# MCU_CTRL_MMR0_CFG0 register map
Vendor: Texas Instruments
Peripheral module from a debugger description file (folder am243x).
Registers are 32-bit, read-write, reset 0x0 unless marked. A register's access mark holds for its fields unless they carry their own. Offsets are as the file gives them; lines under a group give offsets from that group; [hi:lo] are bit positions; {n}, {i} and the like mark numbered series; 'fields as' and 'values as' point back to an identical list; <NAME> marks a mode.

## MCU_CTRL_MMR0_CFG0 (part 1 of 2)
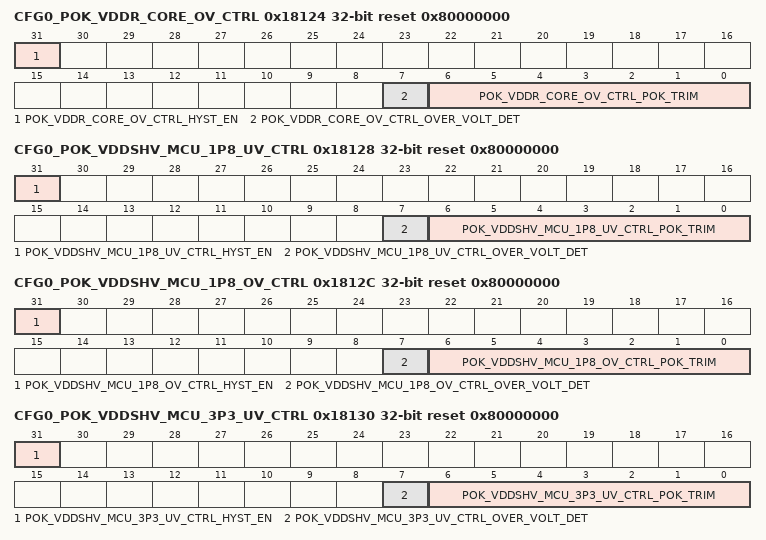
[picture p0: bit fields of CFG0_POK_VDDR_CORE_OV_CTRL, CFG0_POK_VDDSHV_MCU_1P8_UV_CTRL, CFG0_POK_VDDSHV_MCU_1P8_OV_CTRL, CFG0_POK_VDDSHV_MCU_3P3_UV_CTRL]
0x18124 CFG0_POK_VDDR_CORE_OV_CTRL reset 0x80000000
  [31] POK_VDDR_CORE_OV_CTRL_HYST_EN — Active POK hysteresis
  [7] POK_VDDR_CORE_OV_CTRL_OVER_VOLT_DET — Over / under voltage detection mode
  [6:0] POK_VDDR_CORE_OV_CTRL_POK_TRIM — POK Trim Bits
0x18128 CFG0_POK_VDDSHV_MCU_1P8_UV_CTRL reset 0x80000000
  [31] POK_VDDSHV_MCU_1P8_UV_CTRL_HYST_EN — Active POK hysteresis
  [7] POK_VDDSHV_MCU_1P8_UV_CTRL_OVER_VOLT_DET — Over / under voltage detection mode
  [6:0] POK_VDDSHV_MCU_1P8_UV_CTRL_POK_TRIM — POK Trim Bits
0x1812C CFG0_POK_VDDSHV_MCU_1P8_OV_CTRL reset 0x80000000
  [31] POK_VDDSHV_MCU_1P8_OV_CTRL_HYST_EN — Active POK hysteresis
  [7] POK_VDDSHV_MCU_1P8_OV_CTRL_OVER_VOLT_DET — Over / under voltage detection mode
  [6:0] POK_VDDSHV_MCU_1P8_OV_CTRL_POK_TRIM — POK Trim Bits
0x18130 CFG0_POK_VDDSHV_MCU_3P3_UV_CTRL reset 0x80000000
  [31] POK_VDDSHV_MCU_3P3_UV_CTRL_HYST_EN — Active POK hysteresis
  [7] POK_VDDSHV_MCU_3P3_UV_CTRL_OVER_VOLT_DET — Over / under voltage detection mode
  [6:0] POK_VDDSHV_MCU_3P3_UV_CTRL_POK_TRIM — POK Trim Bits
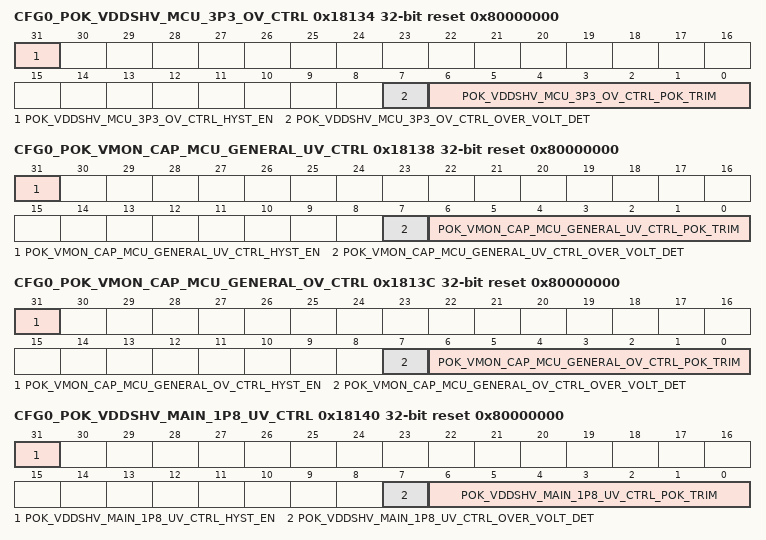
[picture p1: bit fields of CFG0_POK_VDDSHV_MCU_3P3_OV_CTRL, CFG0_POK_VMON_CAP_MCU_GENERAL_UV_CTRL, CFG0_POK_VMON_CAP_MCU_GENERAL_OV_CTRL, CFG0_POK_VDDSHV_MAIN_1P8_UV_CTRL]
0x18134 CFG0_POK_VDDSHV_MCU_3P3_OV_CTRL reset 0x80000000
  [31] POK_VDDSHV_MCU_3P3_OV_CTRL_HYST_EN — Active POK hysteresis
  [7] POK_VDDSHV_MCU_3P3_OV_CTRL_OVER_VOLT_DET — Over / under voltage detection mode
  [6:0] POK_VDDSHV_MCU_3P3_OV_CTRL_POK_TRIM — POK Trim Bits
0x18138 CFG0_POK_VMON_CAP_MCU_GENERAL_UV_CTRL reset 0x80000000
  [31] POK_VMON_CAP_MCU_GENERAL_UV_CTRL_HYST_EN — Active POK hysteresis
  [7] POK_VMON_CAP_MCU_GENERAL_UV_CTRL_OVER_VOLT_DET — Over / under voltage detection mode
  [6:0] POK_VMON_CAP_MCU_GENERAL_UV_CTRL_POK_TRIM — POK Trim Bits
0x1813C CFG0_POK_VMON_CAP_MCU_GENERAL_OV_CTRL reset 0x80000000
  [31] POK_VMON_CAP_MCU_GENERAL_OV_CTRL_HYST_EN — Active POK hysteresis
  [7] POK_VMON_CAP_MCU_GENERAL_OV_CTRL_OVER_VOLT_DET — Over / under voltage detection mode
  [6:0] POK_VMON_CAP_MCU_GENERAL_OV_CTRL_POK_TRIM — POK Trim Bits
0x18140 CFG0_POK_VDDSHV_MAIN_1P8_UV_CTRL reset 0x80000000
  [31] POK_VDDSHV_MAIN_1P8_UV_CTRL_HYST_EN — Active POK hysteresis
  [7] POK_VDDSHV_MAIN_1P8_UV_CTRL_OVER_VOLT_DET — Over / under voltage detection mode
  [6:0] POK_VDDSHV_MAIN_1P8_UV_CTRL_POK_TRIM — POK Trim Bits
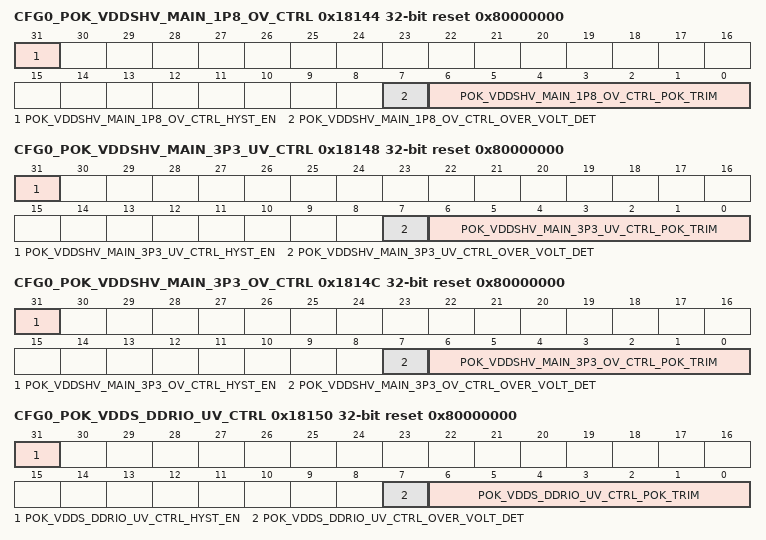
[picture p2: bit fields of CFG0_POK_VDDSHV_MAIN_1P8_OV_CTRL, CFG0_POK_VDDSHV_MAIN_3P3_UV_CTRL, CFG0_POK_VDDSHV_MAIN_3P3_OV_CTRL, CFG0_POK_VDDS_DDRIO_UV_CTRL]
0x18144 CFG0_POK_VDDSHV_MAIN_1P8_OV_CTRL reset 0x80000000
  [31] POK_VDDSHV_MAIN_1P8_OV_CTRL_HYST_EN — Active POK hysteresis
  [7] POK_VDDSHV_MAIN_1P8_OV_CTRL_OVER_VOLT_DET — Over / under voltage detection mode
  [6:0] POK_VDDSHV_MAIN_1P8_OV_CTRL_POK_TRIM — POK Trim Bits
0x18148 CFG0_POK_VDDSHV_MAIN_3P3_UV_CTRL reset 0x80000000
  [31] POK_VDDSHV_MAIN_3P3_UV_CTRL_HYST_EN — Active POK hysteresis
  [7] POK_VDDSHV_MAIN_3P3_UV_CTRL_OVER_VOLT_DET — Over / under voltage detection mode
  [6:0] POK_VDDSHV_MAIN_3P3_UV_CTRL_POK_TRIM — POK Trim Bits
0x1814C CFG0_POK_VDDSHV_MAIN_3P3_OV_CTRL reset 0x80000000
  [31] POK_VDDSHV_MAIN_3P3_OV_CTRL_HYST_EN — Active POK hysteresis
  [7] POK_VDDSHV_MAIN_3P3_OV_CTRL_OVER_VOLT_DET — Over / under voltage detection mode
  [6:0] POK_VDDSHV_MAIN_3P3_OV_CTRL_POK_TRIM — POK Trim Bits
0x18150 CFG0_POK_VDDS_DDRIO_UV_CTRL reset 0x80000000
  [31] POK_VDDS_DDRIO_UV_CTRL_HYST_EN — Active POK hysteresis
  [7] POK_VDDS_DDRIO_UV_CTRL_OVER_VOLT_DET — Over / under voltage detection mode
  [6:0] POK_VDDS_DDRIO_UV_CTRL_POK_TRIM — POK Trim Bits
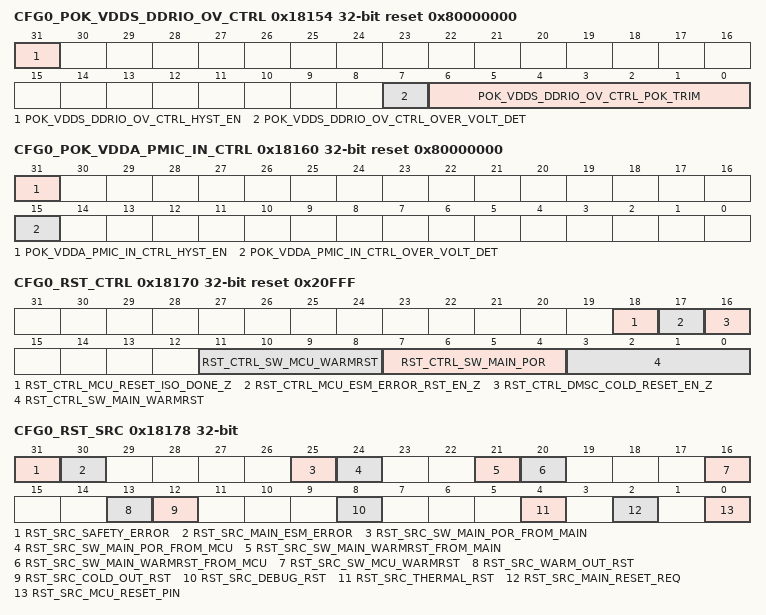
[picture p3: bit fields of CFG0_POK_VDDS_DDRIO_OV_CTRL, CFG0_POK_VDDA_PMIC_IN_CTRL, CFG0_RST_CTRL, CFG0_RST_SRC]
0x18154 CFG0_POK_VDDS_DDRIO_OV_CTRL reset 0x80000000
  [31] POK_VDDS_DDRIO_OV_CTRL_HYST_EN — Active POK hysteresis
  [7] POK_VDDS_DDRIO_OV_CTRL_OVER_VOLT_DET — Over / under voltage detection mode
  [6:0] POK_VDDS_DDRIO_OV_CTRL_POK_TRIM — POK Trim Bits
0x18160 CFG0_POK_VDDA_PMIC_IN_CTRL reset 0x80000000
  [31] POK_VDDA_PMIC_IN_CTRL_HYST_EN — Active POK hysteresis
  [15] POK_VDDA_PMIC_IN_CTRL_OVER_VOLT_DET — Over / under voltage detection mode
0x18170 CFG0_RST_CTRL reset 0x20FFF
  [18] RST_CTRL_MCU_RESET_ISO_DONE_Z — MCU can set this bit to block warm reset in the main domain which is useful when the MCU may be accessing
  [17] RST_CTRL_MCU_ESM_ERROR_RST_EN_Z — Deactivate Reset of MCU by ESM
  [16] RST_CTRL_DMSC_COLD_RESET_EN_Z — Deactivate Reset of MCU by DMSC
  [11:8] RST_CTRL_SW_MCU_WARMRST — This is a fault tolerant bitfield.
  [7:4] RST_CTRL_SW_MAIN_POR — This is a fault tolerant bitfield.
  [3:0] RST_CTRL_SW_MAIN_WARMRST — This is a fault tolerant bitfield.
0x18174 CFG0_RST_STAT ro
  [0] RST_STAT_MAIN_RESETSTATZ — Status of Main Domain Reset:
0x18178 CFG0_RST_SRC
  [31] RST_SRC_SAFETY_ERROR — Reset Caused by MCU ESM Error
  [30] RST_SRC_MAIN_ESM_ERROR — Reset Caused by Main ESM Error
  [25] RST_SRC_SW_MAIN_POR_FROM_MAIN — Software Main Power On Reset From MAIN CTRL MMR
  [24] RST_SRC_SW_MAIN_POR_FROM_MCU — Software Main Power On Reset From MCU CTRL MMR
  [21] RST_SRC_SW_MAIN_WARMRST_FROM_MAIN — Software Main Warm Reset from MAIN CTRL MMR
  [20] RST_SRC_SW_MAIN_WARMRST_FROM_MCU — Software Main Warm Reset From MCU CTRL MMR
  [16] RST_SRC_SW_MCU_WARMRST — Software Warm Reset
  [13] RST_SRC_WARM_OUT_RST — DMSC Warm Reset
  [12] RST_SRC_COLD_OUT_RST — DMSC Cold Reset
  [8] RST_SRC_DEBUG_RST — Debug Subsystem Initiated Reset
  [4] RST_SRC_THERMAL_RST — Thermal Reset
  [2] RST_SRC_MAIN_RESET_REQ — Main Reset Pin
  [0] RST_SRC_MCU_RESET_PIN — Rest Caused by MCU Reset Pin
0x1817C CFG0_RST_MAGIC_WORD
  [31:0] RST_MAGIC_WORD_MCU_MAGIC_WORD — After a MCU_PORz reset this bit field resets to 0x00000000.
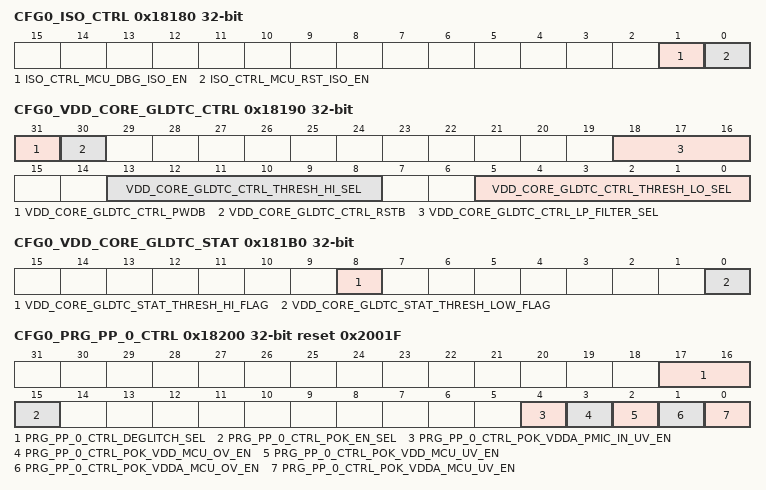
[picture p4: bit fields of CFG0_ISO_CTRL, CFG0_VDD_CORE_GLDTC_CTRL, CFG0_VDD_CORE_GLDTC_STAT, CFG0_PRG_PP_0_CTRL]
0x18180 CFG0_ISO_CTRL
  [1] ISO_CTRL_MCU_DBG_ISO_EN — Isolates the MCU domain from Debug
  [0] ISO_CTRL_MCU_RST_ISO_EN — Isolates the MCU domain from Warm Reset initiated by Main
0x18190 CFG0_VDD_CORE_GLDTC_CTRL
  [31] VDD_CORE_GLDTC_CTRL_PWDB — Power down - active low.
  [30] VDD_CORE_GLDTC_CTRL_RSTB — Reset - active low. To ensure proper operation, rstb must be not be de-asserted for at least 100 ns after power-up (pwdb de-asserted). Additionally, rstb must be toggled low at least 200 ns after any change in threshold or low-pass filter settings to prevent abnormal trigger events.
  [18:16] VDD_CORE_GLDTC_CTRL_LP_FILTER_SEL — Selects the glitch detect low-pass filter bandwidth
  [13:8] VDD_CORE_GLDTC_CTRL_THRESH_HI_SEL — Selects the high voltage glitch threshold as a percentage of the monitored voltage
  [5:0] VDD_CORE_GLDTC_CTRL_THRESH_LO_SEL — Selects the low voltage glitch threshold as a percentage of the monitored voltage
0x181B0 CFG0_VDD_CORE_GLDTC_STAT ro
  [8] VDD_CORE_GLDTC_STAT_THRESH_HI_FLAG — High voltage flag. This flag is cleared by clearing the VDD_CORE_GLDTC_CTRL_rstb bit.
  [0] VDD_CORE_GLDTC_STAT_THRESH_LOW_FLAG — Low voltage flag. This flag is cleared by clearing the VDD_CORE_GLDTC_CTRL_rstb bit.
0x18200 CFG0_PRG_PP_0_CTRL reset 0x2001F
  [17:16] PRG_PP_0_CTRL_DEGLITCH_SEL — Deglitch period for PRG_PP0 POKs:
  [15] PRG_PP_0_CTRL_POK_EN_SEL — Select POK active source
  [4] PRG_PP_0_CTRL_POK_VDDA_PMIC_IN_UV_EN — Active VDDA_PMIC_IN undervoltage POK detection
  [3] PRG_PP_0_CTRL_POK_VDD_MCU_OV_EN — Active VDD_MCU overvoltage POK detection
  [2] PRG_PP_0_CTRL_POK_VDD_MCU_UV_EN — Active VDD_MCU undervoltage POK detection
  [1] PRG_PP_0_CTRL_POK_VDDA_MCU_OV_EN — Active 1.8V VDDA_MCU overvoltage POK detection
  [0] PRG_PP_0_CTRL_POK_VDDA_MCU_UV_EN — Active 1.8V VDDA_MCU undervoltage POK detection
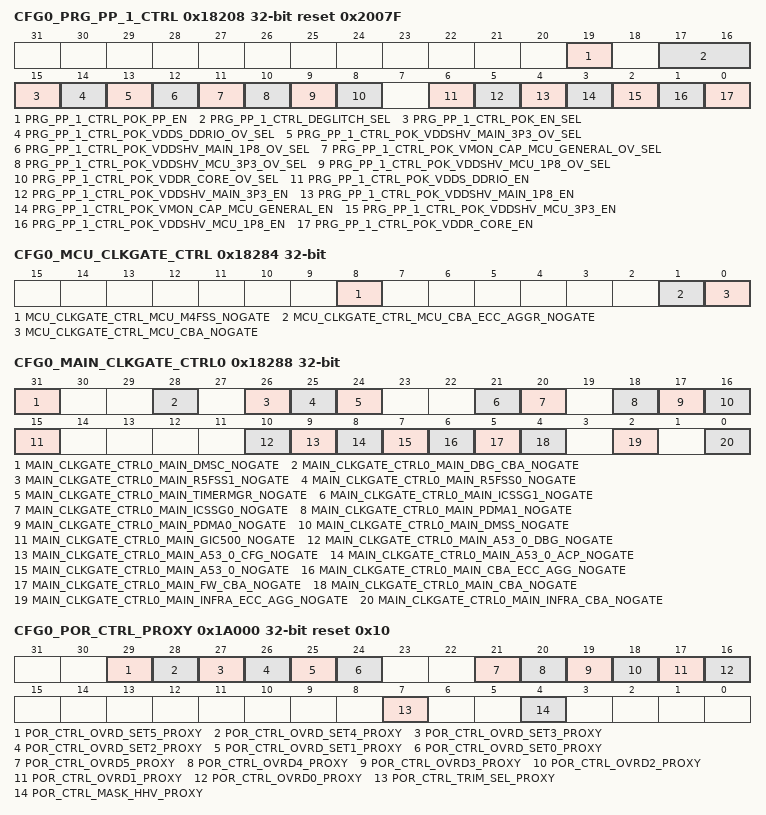
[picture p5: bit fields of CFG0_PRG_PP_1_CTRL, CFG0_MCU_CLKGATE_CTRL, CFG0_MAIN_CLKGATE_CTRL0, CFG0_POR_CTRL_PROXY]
0x18208 CFG0_PRG_PP_1_CTRL reset 0x2007F
  [19] PRG_PP_1_CTRL_POK_PP_EN — POK ping-pong active. When set, activesautomatic switching between undervoltage andovervoltage detection on PRG_PP1 (POK_VDDR_CORE, POK_VDDSHV_MCU_1P8, POK_VDDSHV_MCU_3P3, POK_VMON_CAP_MCU_GENERAL, POK_VDDSHV_MAIN_1P8, POK_VDDSHV_MAIN_3P3, and POK_VDDS_DDRIO) POKs. This bit has no effect if the POK's ov_sel bit = 1.
  [17:16] PRG_PP_1_CTRL_DEGLITCH_SEL — Deglitch period for PRG_PP1 POKs:
  [15] PRG_PP_1_CTRL_POK_EN_SEL — Select POK active source
  [14] PRG_PP_1_CTRL_POK_VDDS_DDRIO_OV_SEL — POK_VDDS_DDRIO mode:
  [13] PRG_PP_1_CTRL_POK_VDDSHV_MAIN_3P3_OV_SEL — POK_VDDSHV_MAIN_3P3 mode:
  [12] PRG_PP_1_CTRL_POK_VDDSHV_MAIN_1P8_OV_SEL — POK_VDDSHV_MAIN_1P8 mode:
  [11] PRG_PP_1_CTRL_POK_VMON_CAP_MCU_GENERAL_OV_SEL — POK_VMON_CAP_MCU_GENERAL mode:
  [10] PRG_PP_1_CTRL_POK_VDDSHV_MCU_3P3_OV_SEL — POK_VDDSHV_MCU_3P3 mode:
  [9] PRG_PP_1_CTRL_POK_VDDSHV_MCU_1P8_OV_SEL — POK_VDDSHV_MCU_1P8 mode:
  [8] PRG_PP_1_CTRL_POK_VDDR_CORE_OV_SEL — POK_VDDR_CORE Mode:
  [6] PRG_PP_1_CTRL_POK_VDDS_DDRIO_EN — Active POK_VDDS_DDRIO (if pok_en_sel = 1):
  [5] PRG_PP_1_CTRL_POK_VDDSHV_MAIN_3P3_EN — Active POK_VDDSHV_MAIN_3P3 (if pok_en_sel = 1):
  [4] PRG_PP_1_CTRL_POK_VDDSHV_MAIN_1P8_EN — Active POK_VDDSHV_MAIN_1P8 (if pok_en_sel = 1):
  [3] PRG_PP_1_CTRL_POK_VMON_CAP_MCU_GENERAL_EN — Active POK_VMON_CAP_MCU_GENERAL (if pok_en_sel = 1):
  [2] PRG_PP_1_CTRL_POK_VDDSHV_MCU_3P3_EN — Active POK_VDDSHV_MCU_3P3 (if pok_en_sel = 1):
  [1] PRG_PP_1_CTRL_POK_VDDSHV_MCU_1P8_EN — Active POK_VDDSHV_MCU_1P8 (if pok_en_sel = 1):
  [0] PRG_PP_1_CTRL_POK_VDDR_CORE_EN — Active POK_VDDR_CORE (if pok_en_sel = 1):
0x18284 CFG0_MCU_CLKGATE_CTRL
  [8] MCU_CLKGATE_CTRL_MCU_M4FSS_NOGATE — MCU domain M4FSS0 clock gate deactivate.
  [1] MCU_CLKGATE_CTRL_MCU_CBA_ECC_AGGR_NOGATE — MCU domain Pulsar clock gate deactivate.
  [0] MCU_CLKGATE_CTRL_MCU_CBA_NOGATE — MCU domain Data bus (mcu_cbass) clock gate deactivate.
0x18288 CFG0_MAIN_CLKGATE_CTRL0
  [31] MAIN_CLKGATE_CTRL0_MAIN_DMSC_NOGATE — MAIN domain DMSC (pwr_dis_nogate) clock gate deactivate.
  [28] MAIN_CLKGATE_CTRL0_MAIN_DBG_CBA_NOGATE — MAIN domain Debug bus clock gate deactivate.
  [26] MAIN_CLKGATE_CTRL0_MAIN_R5FSS1_NOGATE — MAIN domain R5FSS1 clock gate deactivate.
  [25] MAIN_CLKGATE_CTRL0_MAIN_R5FSS0_NOGATE — MAIN domain R5FSS0 clock gate deactivate.
  [24] MAIN_CLKGATE_CTRL0_MAIN_TIMERMGR_NOGATE — MAIN domain TIMERMGR (pwr_dis_nogate) clock gate deactivate.
  [21] MAIN_CLKGATE_CTRL0_MAIN_ICSSG1_NOGATE — MAIN domain ICSSG1 clock gate deactivate.
  [20] MAIN_CLKGATE_CTRL0_MAIN_ICSSG0_NOGATE — MAIN domain ICSSG0 clock gate deactivate.
  [18] MAIN_CLKGATE_CTRL0_MAIN_PDMA1_NOGATE — MAIN domain PDMA1 (pwr_dis_nogate) clock gate deactivate.
  [17] MAIN_CLKGATE_CTRL0_MAIN_PDMA0_NOGATE — MAIN domain PDMA0 (pwr_dis_nogate) clock gate deactivate.
  [16] MAIN_CLKGATE_CTRL0_MAIN_DMSS_NOGATE — MAIN domain DMSS (pwr_dis_nogate) clock gate deactivate.
  [15] MAIN_CLKGATE_CTRL0_MAIN_GIC500_NOGATE — MAIN A53SS0 (gic500_1_2) clock gate deactivate.
  [10] MAIN_CLKGATE_CTRL0_MAIN_A53_0_DBG_NOGATE — MAIN A53SS0 Debug Port clock gate deactivate.
  [9] MAIN_CLKGATE_CTRL0_MAIN_A53_0_CFG_NOGATE — MAIN A53SS0 Configuration Port clock gate deactivate.
  [8] MAIN_CLKGATE_CTRL0_MAIN_A53_0_ACP_NOGATE — MAIN A53SS0 ACP clock gate deactivate.
  [7] MAIN_CLKGATE_CTRL0_MAIN_A53_0_NOGATE — MAIN A53SS0 clock gate deactivate.
  [6] MAIN_CLKGATE_CTRL0_MAIN_CBA_ECC_AGG_NOGATE — MAIN domain data bus ECC aggragator (main_cba_ecc_aggr_main_0) clock gate deactivate.
  [5] MAIN_CLKGATE_CTRL0_MAIN_FW_CBA_NOGATE — MAIN domain datal bus (main_fw_cbass) clock gate deactivate.
  [4] MAIN_CLKGATE_CTRL0_MAIN_CBA_NOGATE — MAIN domain data bus (main_cbass) clock gate deactivate.
  [2] MAIN_CLKGATE_CTRL0_MAIN_INFRA_ECC_AGG_NOGATE — MAIN domain Infrastructure ECC aggragator (main_infra_ecc_aggr) clock gate deactivate.
  [0] MAIN_CLKGATE_CTRL0_MAIN_INFRA_CBA_NOGATE — MAIN domain Infrastructure bus (main_infra_cbass) clock gate deactivate.
0x19008 CFG0_LOCK6_KICK0
  [31:0] LOCK6_KICK0 — - KICK0 component
0x1900C CFG0_LOCK6_KICK1
  [31:0] LOCK6_KICK1 — - KICK1 component
{0x19100+4i} CFG0_CLAIMREG_P6_R{i}_READONLY ro (i=0..5)
  [31:0] CLAIMREG_P6_R{i}_READONLY — Claim bits for Partition 6
0x1A000 CFG0_POR_CTRL_PROXY reset 0x10
  [29] POR_CTRL_OVRD_SET5_PROXY — Reserved override set
  [28] POR_CTRL_OVRD_SET4_PROXY — POKLVB override set
  [27] POR_CTRL_OVRD_SET3_PROXY — POKLVA override set
  [26] POR_CTRL_OVRD_SET2_PROXY — POKHV override set
  [25] POR_CTRL_OVRD_SET1_PROXY — BGOK override set
  [24] POR_CTRL_OVRD_SET0_PROXY — PORHV override set
  [21] POR_CTRL_OVRD5_PROXY — Reserved override active
  [20] POR_CTRL_OVRD4_PROXY — POKLVB override active
  [19] POR_CTRL_OVRD3_PROXY — POKLVA override active
  [18] POR_CTRL_OVRD2_PROXY — POKHV override active
  [17] POR_CTRL_OVRD1_PROXY — BGOK override active
  [16] POR_CTRL_OVRD0_PROXY — PORHV override active
  [7] POR_CTRL_TRIM_SEL_PROXY — POR Trim Select
  [4] POR_CTRL_MASK_HHV_PROXY — Mask HHV/SOC_PORz outputs when applying new trim values
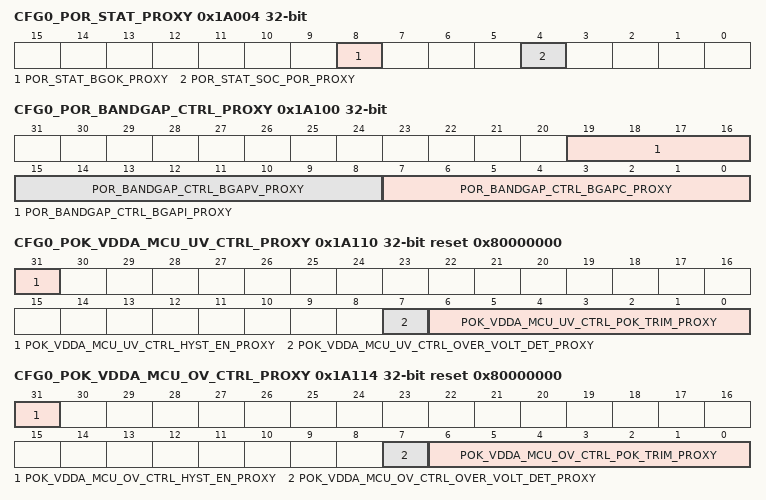
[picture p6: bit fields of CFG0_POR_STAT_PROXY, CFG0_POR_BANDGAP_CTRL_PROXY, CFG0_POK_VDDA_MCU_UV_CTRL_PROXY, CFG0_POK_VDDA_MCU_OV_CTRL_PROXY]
0x1A004 CFG0_POR_STAT_PROXY ro
  [8] POR_STAT_BGOK_PROXY — Bandgap OK status
  [4] POR_STAT_SOC_POR_PROXY — POR module status
0x1A100 CFG0_POR_BANDGAP_CTRL_PROXY
  [19:16] POR_BANDGAP_CTRL_BGAPI_PROXY — Bandgap output current trim bits
  [15:8] POR_BANDGAP_CTRL_BGAPV_PROXY — Bandgap output voltage magnitude trim bits
  [7:0] POR_BANDGAP_CTRL_BGAPC_PROXY — Bandgap slope trim bits. Bit7 is used to calculate the offset
0x1A110 CFG0_POK_VDDA_MCU_UV_CTRL_PROXY reset 0x80000000
  [31] POK_VDDA_MCU_UV_CTRL_HYST_EN_PROXY — Active POK hysteresis
  [7] POK_VDDA_MCU_UV_CTRL_OVER_VOLT_DET_PROXY — Over / under voltage detection mode
  [6:0] POK_VDDA_MCU_UV_CTRL_POK_TRIM_PROXY — POK Trim Bits
0x1A114 CFG0_POK_VDDA_MCU_OV_CTRL_PROXY reset 0x80000000
  [31] POK_VDDA_MCU_OV_CTRL_HYST_EN_PROXY — Active POK hysteresis
  [7] POK_VDDA_MCU_OV_CTRL_OVER_VOLT_DET_PROXY — Over / under voltage detection mode
  [6:0] POK_VDDA_MCU_OV_CTRL_POK_TRIM_PROXY — POK Trim Bits
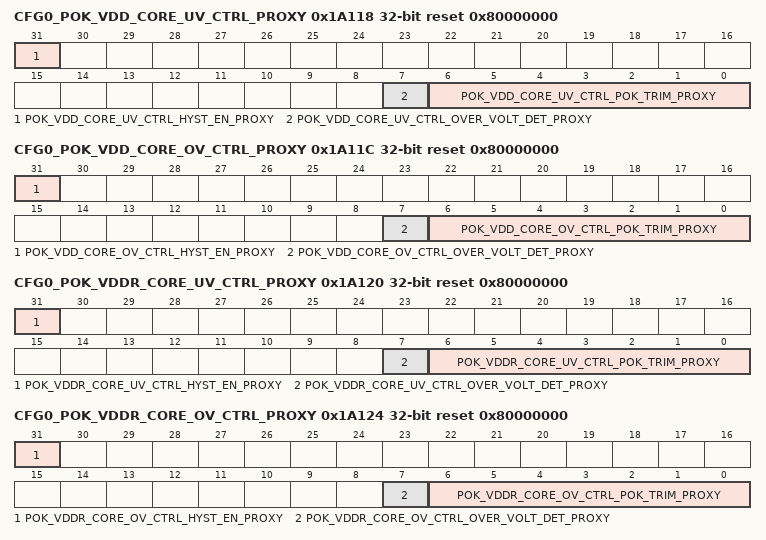
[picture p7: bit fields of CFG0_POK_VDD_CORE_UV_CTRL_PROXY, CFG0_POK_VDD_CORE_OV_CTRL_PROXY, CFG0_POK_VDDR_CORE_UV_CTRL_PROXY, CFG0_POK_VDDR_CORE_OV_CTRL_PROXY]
0x1A118 CFG0_POK_VDD_CORE_UV_CTRL_PROXY reset 0x80000000
  [31] POK_VDD_CORE_UV_CTRL_HYST_EN_PROXY — Active POK hysteresis
  [7] POK_VDD_CORE_UV_CTRL_OVER_VOLT_DET_PROXY — Over / under voltage detection mode
  [6:0] POK_VDD_CORE_UV_CTRL_POK_TRIM_PROXY — POK Trim Bits
0x1A11C CFG0_POK_VDD_CORE_OV_CTRL_PROXY reset 0x80000000
  [31] POK_VDD_CORE_OV_CTRL_HYST_EN_PROXY — Active POK hysteresis
  [7] POK_VDD_CORE_OV_CTRL_OVER_VOLT_DET_PROXY — Over / under voltage detection mode
  [6:0] POK_VDD_CORE_OV_CTRL_POK_TRIM_PROXY — POK Trim Bits
0x1A120 CFG0_POK_VDDR_CORE_UV_CTRL_PROXY reset 0x80000000
  [31] POK_VDDR_CORE_UV_CTRL_HYST_EN_PROXY — Active POK hysteresis
  [7] POK_VDDR_CORE_UV_CTRL_OVER_VOLT_DET_PROXY — Over / under voltage detection mode
  [6:0] POK_VDDR_CORE_UV_CTRL_POK_TRIM_PROXY — POK Trim Bits
0x1A124 CFG0_POK_VDDR_CORE_OV_CTRL_PROXY reset 0x80000000
  [31] POK_VDDR_CORE_OV_CTRL_HYST_EN_PROXY — Active POK hysteresis
  [7] POK_VDDR_CORE_OV_CTRL_OVER_VOLT_DET_PROXY — Over / under voltage detection mode
  [6:0] POK_VDDR_CORE_OV_CTRL_POK_TRIM_PROXY — POK Trim Bits
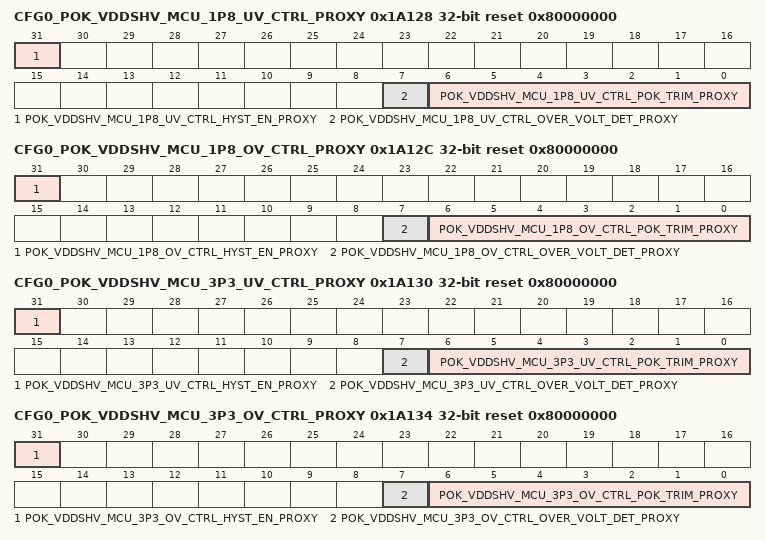
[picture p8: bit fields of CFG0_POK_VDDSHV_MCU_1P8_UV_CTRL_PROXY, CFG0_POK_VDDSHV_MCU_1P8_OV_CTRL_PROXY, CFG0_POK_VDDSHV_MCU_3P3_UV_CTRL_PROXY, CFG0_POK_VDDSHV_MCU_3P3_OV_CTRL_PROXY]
0x1A128 CFG0_POK_VDDSHV_MCU_1P8_UV_CTRL_PROXY reset 0x80000000
  [31] POK_VDDSHV_MCU_1P8_UV_CTRL_HYST_EN_PROXY — Active POK hysteresis
  [7] POK_VDDSHV_MCU_1P8_UV_CTRL_OVER_VOLT_DET_PROXY — Over / under voltage detection mode
  [6:0] POK_VDDSHV_MCU_1P8_UV_CTRL_POK_TRIM_PROXY — POK Trim Bits
0x1A12C CFG0_POK_VDDSHV_MCU_1P8_OV_CTRL_PROXY reset 0x80000000
  [31] POK_VDDSHV_MCU_1P8_OV_CTRL_HYST_EN_PROXY — Active POK hysteresis
  [7] POK_VDDSHV_MCU_1P8_OV_CTRL_OVER_VOLT_DET_PROXY — Over / under voltage detection mode
  [6:0] POK_VDDSHV_MCU_1P8_OV_CTRL_POK_TRIM_PROXY — POK Trim Bits
0x1A130 CFG0_POK_VDDSHV_MCU_3P3_UV_CTRL_PROXY reset 0x80000000
  [31] POK_VDDSHV_MCU_3P3_UV_CTRL_HYST_EN_PROXY — Active POK hysteresis
  [7] POK_VDDSHV_MCU_3P3_UV_CTRL_OVER_VOLT_DET_PROXY — Over / under voltage detection mode
  [6:0] POK_VDDSHV_MCU_3P3_UV_CTRL_POK_TRIM_PROXY — POK Trim Bits
0x1A134 CFG0_POK_VDDSHV_MCU_3P3_OV_CTRL_PROXY reset 0x80000000
  [31] POK_VDDSHV_MCU_3P3_OV_CTRL_HYST_EN_PROXY — Active POK hysteresis
  [7] POK_VDDSHV_MCU_3P3_OV_CTRL_OVER_VOLT_DET_PROXY — Over / under voltage detection mode
  [6:0] POK_VDDSHV_MCU_3P3_OV_CTRL_POK_TRIM_PROXY — POK Trim Bits
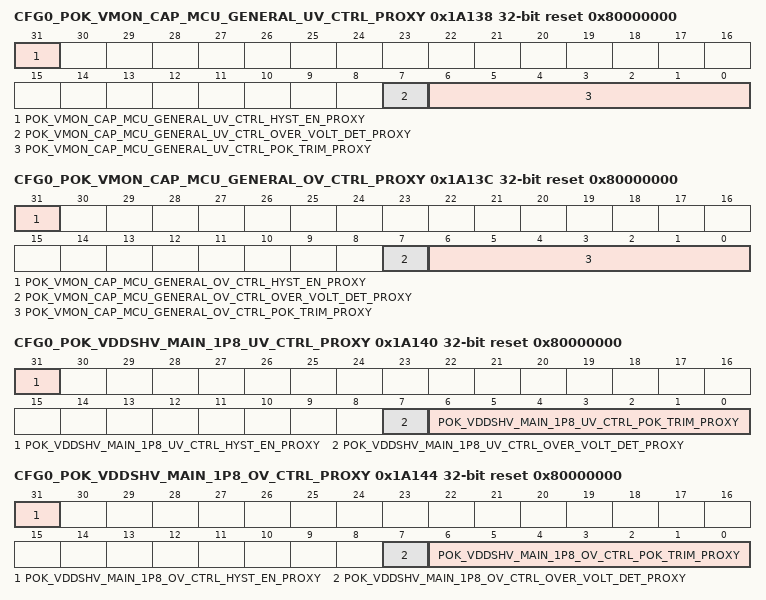
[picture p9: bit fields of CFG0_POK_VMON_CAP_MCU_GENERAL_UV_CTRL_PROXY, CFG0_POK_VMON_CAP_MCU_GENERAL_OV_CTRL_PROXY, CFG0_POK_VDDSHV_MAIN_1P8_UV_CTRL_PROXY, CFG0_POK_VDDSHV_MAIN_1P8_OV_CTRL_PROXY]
0x1A138 CFG0_POK_VMON_CAP_MCU_GENERAL_UV_CTRL_PROXY reset 0x80000000
  [31] POK_VMON_CAP_MCU_GENERAL_UV_CTRL_HYST_EN_PROXY — Active POK hysteresis
  [7] POK_VMON_CAP_MCU_GENERAL_UV_CTRL_OVER_VOLT_DET_PROXY — Over / under voltage detection mode
  [6:0] POK_VMON_CAP_MCU_GENERAL_UV_CTRL_POK_TRIM_PROXY — POK Trim Bits
0x1A13C CFG0_POK_VMON_CAP_MCU_GENERAL_OV_CTRL_PROXY reset 0x80000000
  [31] POK_VMON_CAP_MCU_GENERAL_OV_CTRL_HYST_EN_PROXY — Active POK hysteresis
  [7] POK_VMON_CAP_MCU_GENERAL_OV_CTRL_OVER_VOLT_DET_PROXY — Over / under voltage detection mode
  [6:0] POK_VMON_CAP_MCU_GENERAL_OV_CTRL_POK_TRIM_PROXY — POK Trim Bits
0x1A140 CFG0_POK_VDDSHV_MAIN_1P8_UV_CTRL_PROXY reset 0x80000000
  [31] POK_VDDSHV_MAIN_1P8_UV_CTRL_HYST_EN_PROXY — Active POK hysteresis
  [7] POK_VDDSHV_MAIN_1P8_UV_CTRL_OVER_VOLT_DET_PROXY — Over / under voltage detection mode
  [6:0] POK_VDDSHV_MAIN_1P8_UV_CTRL_POK_TRIM_PROXY — POK Trim Bits
0x1A144 CFG0_POK_VDDSHV_MAIN_1P8_OV_CTRL_PROXY reset 0x80000000
  [31] POK_VDDSHV_MAIN_1P8_OV_CTRL_HYST_EN_PROXY — Active POK hysteresis
  [7] POK_VDDSHV_MAIN_1P8_OV_CTRL_OVER_VOLT_DET_PROXY — Over / under voltage detection mode
  [6:0] POK_VDDSHV_MAIN_1P8_OV_CTRL_POK_TRIM_PROXY — POK Trim Bits
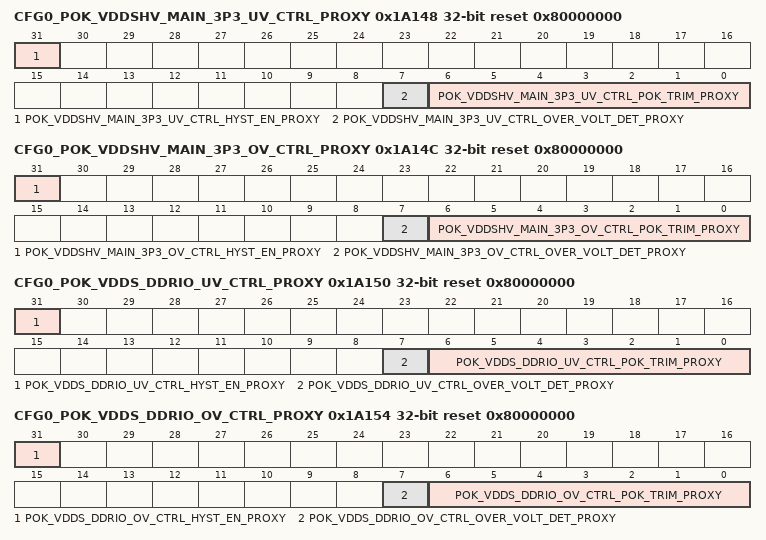
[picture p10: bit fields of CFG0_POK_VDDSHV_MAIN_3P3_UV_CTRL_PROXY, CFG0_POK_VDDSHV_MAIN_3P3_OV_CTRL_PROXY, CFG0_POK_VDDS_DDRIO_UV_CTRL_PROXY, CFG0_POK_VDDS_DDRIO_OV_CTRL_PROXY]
0x1A148 CFG0_POK_VDDSHV_MAIN_3P3_UV_CTRL_PROXY reset 0x80000000
  [31] POK_VDDSHV_MAIN_3P3_UV_CTRL_HYST_EN_PROXY — Active POK hysteresis
  [7] POK_VDDSHV_MAIN_3P3_UV_CTRL_OVER_VOLT_DET_PROXY — Over / under voltage detection mode
  [6:0] POK_VDDSHV_MAIN_3P3_UV_CTRL_POK_TRIM_PROXY — POK Trim Bits
0x1A14C CFG0_POK_VDDSHV_MAIN_3P3_OV_CTRL_PROXY reset 0x80000000
  [31] POK_VDDSHV_MAIN_3P3_OV_CTRL_HYST_EN_PROXY — Active POK hysteresis
  [7] POK_VDDSHV_MAIN_3P3_OV_CTRL_OVER_VOLT_DET_PROXY — Over / under voltage detection mode
  [6:0] POK_VDDSHV_MAIN_3P3_OV_CTRL_POK_TRIM_PROXY — POK Trim Bits
0x1A150 CFG0_POK_VDDS_DDRIO_UV_CTRL_PROXY reset 0x80000000
  [31] POK_VDDS_DDRIO_UV_CTRL_HYST_EN_PROXY — Active POK hysteresis
  [7] POK_VDDS_DDRIO_UV_CTRL_OVER_VOLT_DET_PROXY — Over / under voltage detection mode
  [6:0] POK_VDDS_DDRIO_UV_CTRL_POK_TRIM_PROXY — POK Trim Bits
0x1A154 CFG0_POK_VDDS_DDRIO_OV_CTRL_PROXY reset 0x80000000
  [31] POK_VDDS_DDRIO_OV_CTRL_HYST_EN_PROXY — Active POK hysteresis
  [7] POK_VDDS_DDRIO_OV_CTRL_OVER_VOLT_DET_PROXY — Over / under voltage detection mode
  [6:0] POK_VDDS_DDRIO_OV_CTRL_POK_TRIM_PROXY — POK Trim Bits
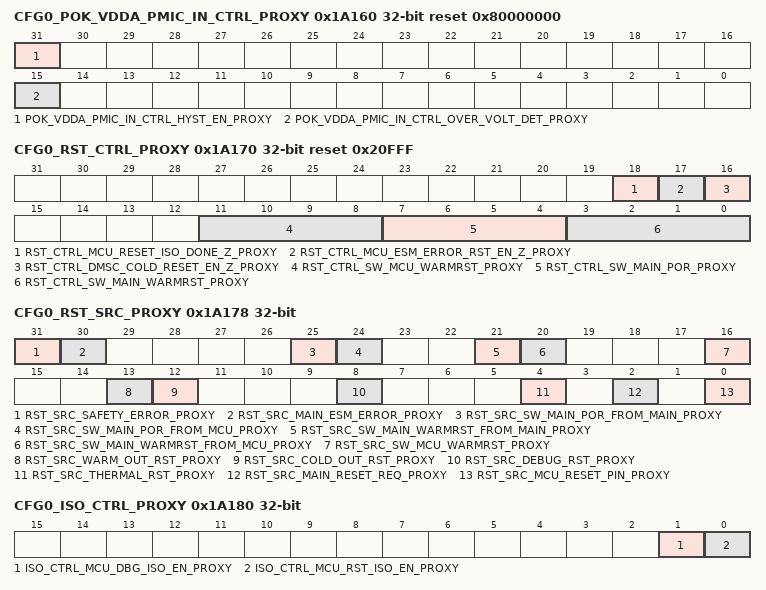
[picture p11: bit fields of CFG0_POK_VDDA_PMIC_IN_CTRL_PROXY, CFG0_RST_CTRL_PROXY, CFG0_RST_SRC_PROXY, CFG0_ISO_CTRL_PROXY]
0x1A160 CFG0_POK_VDDA_PMIC_IN_CTRL_PROXY reset 0x80000000
  [31] POK_VDDA_PMIC_IN_CTRL_HYST_EN_PROXY — Active POK hysteresis
  [15] POK_VDDA_PMIC_IN_CTRL_OVER_VOLT_DET_PROXY — Over / under voltage detection mode
0x1A170 CFG0_RST_CTRL_PROXY reset 0x20FFF
  [18] RST_CTRL_MCU_RESET_ISO_DONE_Z_PROXY — MCU can set this bit to block warm reset in the main domain which is useful when the MCU may be accessing
  [17] RST_CTRL_MCU_ESM_ERROR_RST_EN_Z_PROXY — Deactivate Reset of MCU by ESM
  [16] RST_CTRL_DMSC_COLD_RESET_EN_Z_PROXY — Deactivate Reset of MCU by DMSC
  [11:8] RST_CTRL_SW_MCU_WARMRST_PROXY — This is a fault tolerant bitfield.
  [7:4] RST_CTRL_SW_MAIN_POR_PROXY — This is a fault tolerant bitfield.
  [3:0] RST_CTRL_SW_MAIN_WARMRST_PROXY — This is a fault tolerant bitfield.
0x1A174 CFG0_RST_STAT_PROXY ro
  [0] RST_STAT_MAIN_RESETSTATZ_PROXY — Status of Main Domain Reset:
0x1A178 CFG0_RST_SRC_PROXY
  [31] RST_SRC_SAFETY_ERROR_PROXY — Reset Caused by MCU ESM Error
  [30] RST_SRC_MAIN_ESM_ERROR_PROXY — Reset Caused by Main ESM Error
  [25] RST_SRC_SW_MAIN_POR_FROM_MAIN_PROXY — Software Main Power On Reset From MAIN CTRL MMR
  [24] RST_SRC_SW_MAIN_POR_FROM_MCU_PROXY — Software Main Power On Reset From MCU CTRL MMR
  [21] RST_SRC_SW_MAIN_WARMRST_FROM_MAIN_PROXY — Software Main Warm Reset from MAIN CTRL MMR
  [20] RST_SRC_SW_MAIN_WARMRST_FROM_MCU_PROXY — Software Main Warm Reset From MCU CTRL MMR
  [16] RST_SRC_SW_MCU_WARMRST_PROXY — Software Warm Reset
  [13] RST_SRC_WARM_OUT_RST_PROXY — DMSC Warm Reset
  [12] RST_SRC_COLD_OUT_RST_PROXY — DMSC Cold Reset
  [8] RST_SRC_DEBUG_RST_PROXY — Debug Subsystem Initiated Reset
  [4] RST_SRC_THERMAL_RST_PROXY — Thermal Reset
  [2] RST_SRC_MAIN_RESET_REQ_PROXY — Main Reset Pin
  [0] RST_SRC_MCU_RESET_PIN_PROXY — Rest Caused by MCU Reset Pin
0x1A17C CFG0_RST_MAGIC_WORD_PROXY
  [31:0] RST_MAGIC_WORD_MCU_MAGIC_WORD_PROXY — After a MCU_PORz reset this bit field resets to 0x00000000.
0x1A180 CFG0_ISO_CTRL_PROXY
  [1] ISO_CTRL_MCU_DBG_ISO_EN_PROXY — Isolates the MCU domain from Debug
  [0] ISO_CTRL_MCU_RST_ISO_EN_PROXY — Isolates the MCU domain from Warm Reset initiated by Main
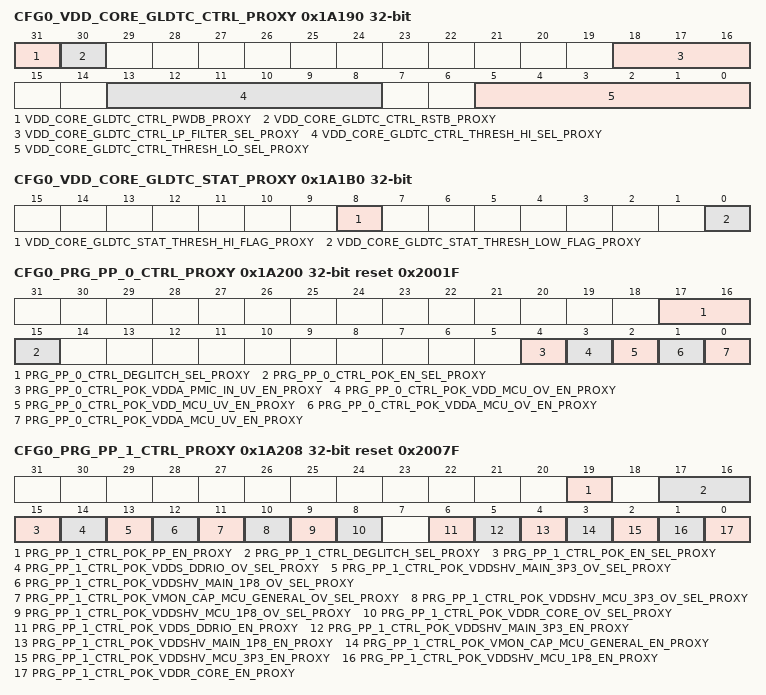
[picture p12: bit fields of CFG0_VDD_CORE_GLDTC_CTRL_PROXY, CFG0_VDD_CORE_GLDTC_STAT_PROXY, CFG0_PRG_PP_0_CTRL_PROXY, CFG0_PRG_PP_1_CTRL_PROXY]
0x1A190 CFG0_VDD_CORE_GLDTC_CTRL_PROXY
  [31] VDD_CORE_GLDTC_CTRL_PWDB_PROXY — Power down - active low.
  [30] VDD_CORE_GLDTC_CTRL_RSTB_PROXY — Reset - active low. To ensure proper operation, rstb must be not be de-asserted for at least 100 ns after power-up (pwdb de-asserted). Additionally, rstb must be toggled low at least 200 ns after any change in threshold or low-pass filter settings to prevent abnormal trigger events.
  [18:16] VDD_CORE_GLDTC_CTRL_LP_FILTER_SEL_PROXY — Selects the glitch detect low-pass filter bandwidth
  [13:8] VDD_CORE_GLDTC_CTRL_THRESH_HI_SEL_PROXY — Selects the high voltage glitch threshold as a percentage of the monitored voltage
  [5:0] VDD_CORE_GLDTC_CTRL_THRESH_LO_SEL_PROXY — Selects the low voltage glitch threshold as a percentage of the monitored voltage
0x1A1B0 CFG0_VDD_CORE_GLDTC_STAT_PROXY ro
  [8] VDD_CORE_GLDTC_STAT_THRESH_HI_FLAG_PROXY — High voltage flag. This flag is cleared by clearing the VDD_CORE_GLDTC_CTRL_rstb bit.
  [0] VDD_CORE_GLDTC_STAT_THRESH_LOW_FLAG_PROXY — Low voltage flag. This flag is cleared by clearing the VDD_CORE_GLDTC_CTRL_rstb bit.
0x1A200 CFG0_PRG_PP_0_CTRL_PROXY reset 0x2001F
  [17:16] PRG_PP_0_CTRL_DEGLITCH_SEL_PROXY — Deglitch period for PRG_PP0 POKs:
  [15] PRG_PP_0_CTRL_POK_EN_SEL_PROXY — Select POK active source
  [4] PRG_PP_0_CTRL_POK_VDDA_PMIC_IN_UV_EN_PROXY — Active VDDA_PMIC_IN undervoltage POK detection
  [3] PRG_PP_0_CTRL_POK_VDD_MCU_OV_EN_PROXY — Active VDD_MCU overvoltage POK detection
  [2] PRG_PP_0_CTRL_POK_VDD_MCU_UV_EN_PROXY — Active VDD_MCU undervoltage POK detection
  [1] PRG_PP_0_CTRL_POK_VDDA_MCU_OV_EN_PROXY — Active 1.8V VDDA_MCU overvoltage POK detection
  [0] PRG_PP_0_CTRL_POK_VDDA_MCU_UV_EN_PROXY — Active 1.8V VDDA_MCU undervoltage POK detection
0x1A208 CFG0_PRG_PP_1_CTRL_PROXY reset 0x2007F
  [19] PRG_PP_1_CTRL_POK_PP_EN_PROXY — POK ping-pong active. When set, activesautomatic switching between undervoltage andovervoltage detection on PRG_PP1 (POK_VDDR_CORE, POK_VDDSHV_MCU_1P8, POK_VDDSHV_MCU_3P3, POK_VMON_CAP_MCU_GENERAL, POK_VDDSHV_MAIN_1P8, POK_VDDSHV_MAIN_3P3, and POK_VDDS_DDRIO) POKs. This bit has no effect if the POK's ov_sel bit = 1.
  [17:16] PRG_PP_1_CTRL_DEGLITCH_SEL_PROXY — Deglitch period for PRG_PP1 POKs:
  [15] PRG_PP_1_CTRL_POK_EN_SEL_PROXY — Select POK active source
  [14] PRG_PP_1_CTRL_POK_VDDS_DDRIO_OV_SEL_PROXY — POK_VDDS_DDRIO mode:
  [13] PRG_PP_1_CTRL_POK_VDDSHV_MAIN_3P3_OV_SEL_PROXY — POK_VDDSHV_MAIN_3P3 mode:
  [12] PRG_PP_1_CTRL_POK_VDDSHV_MAIN_1P8_OV_SEL_PROXY — POK_VDDSHV_MAIN_1P8 mode:
  [11] PRG_PP_1_CTRL_POK_VMON_CAP_MCU_GENERAL_OV_SEL_PROXY — POK_VMON_CAP_MCU_GENERAL mode:
  [10] PRG_PP_1_CTRL_POK_VDDSHV_MCU_3P3_OV_SEL_PROXY — POK_VDDSHV_MCU_3P3 mode:
  [9] PRG_PP_1_CTRL_POK_VDDSHV_MCU_1P8_OV_SEL_PROXY — POK_VDDSHV_MCU_1P8 mode:
  [8] PRG_PP_1_CTRL_POK_VDDR_CORE_OV_SEL_PROXY — POK_VDDR_CORE Mode:
  [6] PRG_PP_1_CTRL_POK_VDDS_DDRIO_EN_PROXY — Active POK_VDDS_DDRIO (if pok_en_sel = 1):
  [5] PRG_PP_1_CTRL_POK_VDDSHV_MAIN_3P3_EN_PROXY — Active POK_VDDSHV_MAIN_3P3 (if pok_en_sel = 1):
  [4] PRG_PP_1_CTRL_POK_VDDSHV_MAIN_1P8_EN_PROXY — Active POK_VDDSHV_MAIN_1P8 (if pok_en_sel = 1):
  [3] PRG_PP_1_CTRL_POK_VMON_CAP_MCU_GENERAL_EN_PROXY — Active POK_VMON_CAP_MCU_GENERAL (if pok_en_sel = 1):
  [2] PRG_PP_1_CTRL_POK_VDDSHV_MCU_3P3_EN_PROXY — Active POK_VDDSHV_MCU_3P3 (if pok_en_sel = 1):
  [1] PRG_PP_1_CTRL_POK_VDDSHV_MCU_1P8_EN_PROXY — Active POK_VDDSHV_MCU_1P8 (if pok_en_sel = 1):
  [0] PRG_PP_1_CTRL_POK_VDDR_CORE_EN_PROXY — Active POK_VDDR_CORE (if pok_en_sel = 1):
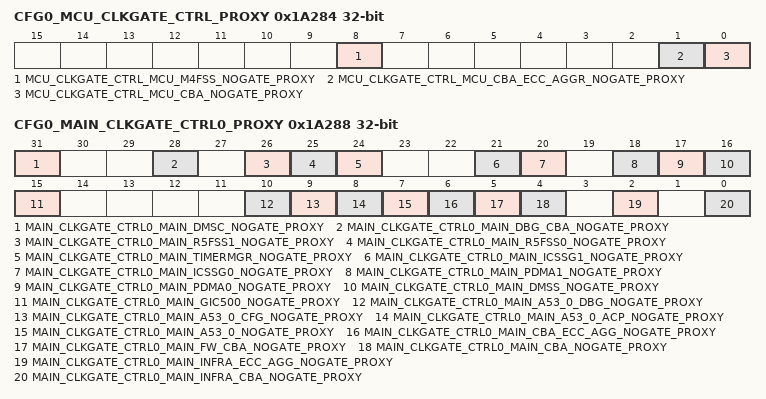
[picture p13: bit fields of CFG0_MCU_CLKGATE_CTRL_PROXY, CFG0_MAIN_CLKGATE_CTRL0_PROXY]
0x1A284 CFG0_MCU_CLKGATE_CTRL_PROXY
  [8] MCU_CLKGATE_CTRL_MCU_M4FSS_NOGATE_PROXY — MCU domain M4FSS0 clock gate deactivate.
  [1] MCU_CLKGATE_CTRL_MCU_CBA_ECC_AGGR_NOGATE_PROXY — MCU domain Pulsar clock gate deactivate.
  [0] MCU_CLKGATE_CTRL_MCU_CBA_NOGATE_PROXY — MCU domain Data bus (mcu_cbass) clock gate deactivate.
0x1A288 CFG0_MAIN_CLKGATE_CTRL0_PROXY
  [31] MAIN_CLKGATE_CTRL0_MAIN_DMSC_NOGATE_PROXY — MAIN domain DMSC (pwr_dis_nogate) clock gate deactivate.
  [28] MAIN_CLKGATE_CTRL0_MAIN_DBG_CBA_NOGATE_PROXY — MAIN domain Debug bus clock gate deactivate.
  [26] MAIN_CLKGATE_CTRL0_MAIN_R5FSS1_NOGATE_PROXY — MAIN domain R5FSS1 clock gate deactivate.
  [25] MAIN_CLKGATE_CTRL0_MAIN_R5FSS0_NOGATE_PROXY — MAIN domain R5FSS0 clock gate deactivate.
  [24] MAIN_CLKGATE_CTRL0_MAIN_TIMERMGR_NOGATE_PROXY — MAIN domain TIMERMGR (pwr_dis_nogate) clock gate deactivate.
  [21] MAIN_CLKGATE_CTRL0_MAIN_ICSSG1_NOGATE_PROXY — MAIN domain ICSSG1 clock gate deactivate.
  [20] MAIN_CLKGATE_CTRL0_MAIN_ICSSG0_NOGATE_PROXY — MAIN domain ICSSG0 clock gate deactivate.
  [18] MAIN_CLKGATE_CTRL0_MAIN_PDMA1_NOGATE_PROXY — MAIN domain PDMA1 (pwr_dis_nogate) clock gate deactivate.
  [17] MAIN_CLKGATE_CTRL0_MAIN_PDMA0_NOGATE_PROXY — MAIN domain PDMA0 (pwr_dis_nogate) clock gate deactivate.
  [16] MAIN_CLKGATE_CTRL0_MAIN_DMSS_NOGATE_PROXY — MAIN domain DMSS (pwr_dis_nogate) clock gate deactivate.
  [15] MAIN_CLKGATE_CTRL0_MAIN_GIC500_NOGATE_PROXY — MAIN A53SS0 (gic500_1_2) clock gate deactivate.
  [10] MAIN_CLKGATE_CTRL0_MAIN_A53_0_DBG_NOGATE_PROXY — MAIN A53SS0 Debug Port clock gate deactivate.
  [9] MAIN_CLKGATE_CTRL0_MAIN_A53_0_CFG_NOGATE_PROXY — MAIN A53SS0 Configuration Port clock gate deactivate.
  [8] MAIN_CLKGATE_CTRL0_MAIN_A53_0_ACP_NOGATE_PROXY — MAIN A53SS0 ACP clock gate deactivate.
  [7] MAIN_CLKGATE_CTRL0_MAIN_A53_0_NOGATE_PROXY — MAIN A53SS0 clock gate deactivate.
  [6] MAIN_CLKGATE_CTRL0_MAIN_CBA_ECC_AGG_NOGATE_PROXY — MAIN domain data bus ECC aggragator (main_cba_ecc_aggr_main_0) clock gate deactivate.
  [5] MAIN_CLKGATE_CTRL0_MAIN_FW_CBA_NOGATE_PROXY — MAIN domain datal bus (main_fw_cbass) clock gate deactivate.
  [4] MAIN_CLKGATE_CTRL0_MAIN_CBA_NOGATE_PROXY — MAIN domain data bus (main_cbass) clock gate deactivate.
  [2] MAIN_CLKGATE_CTRL0_MAIN_INFRA_ECC_AGG_NOGATE_PROXY — MAIN domain Infrastructure ECC aggragator (main_infra_ecc_aggr) clock gate deactivate.
  [0] MAIN_CLKGATE_CTRL0_MAIN_INFRA_CBA_NOGATE_PROXY — MAIN domain Infrastructure bus (main_infra_cbass) clock gate deactivate.
0x1B008 CFG0_LOCK6_KICK0_PROXY
  [31:0] LOCK6_KICK0_PROXY — - KICK0 component
0x1B00C CFG0_LOCK6_KICK1_PROXY
  [31:0] LOCK6_KICK1_PROXY — - KICK1 component
{0x1B100+4i} CFG0_CLAIMREG_P6_R{i} (i=0..5)
  [31:0] CLAIMREG_P6_R{i} — Claim bits for Partition 6
